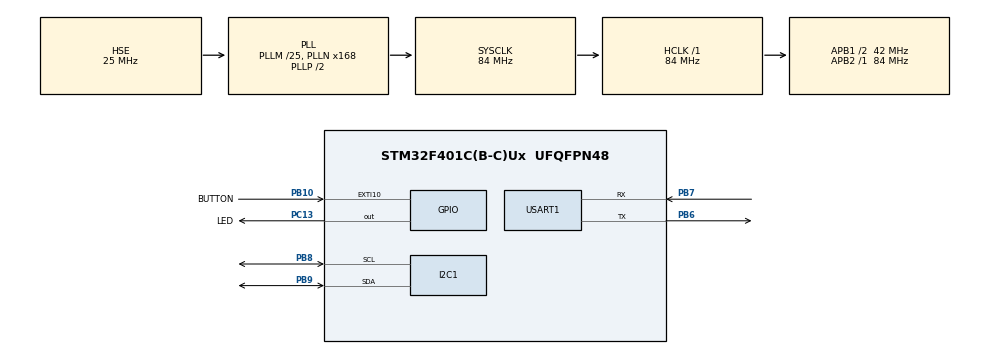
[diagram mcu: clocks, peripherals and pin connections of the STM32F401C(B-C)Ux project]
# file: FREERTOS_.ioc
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FREERTOS.BinarySemaphores01=semTrans,Dynamic,NULL
FREERTOS.Tasks01=TaskWrite,24,128,StartTaskWrite,Default,NULL,Dynamic,NULL,NULL;TaskRead,24,128,StartTaskRead,Default,NULL,Dynamic,NULL,NULL
FREERTOS.configTICK_RATE_HZ=500
FREERTOS.configUSE_NEWLIB_REENTRANT=1
Mcu.Family=STM32F4
Mcu.Name=STM32F401C(B-C)Ux
Mcu.Package=UFQFPN48
NVIC.EXTI15_10_IRQn=true\:5\:0\:false\:false\:true\:true\:true\:true\:true
NVIC.PriorityGroup=NVIC_PRIORITYGROUP_4
NVIC.RCC_IRQn=true\:5\:0\:false\:false\:true\:true\:true\:false\:true
PA13.Mode=Serial_Wire
PA13.Signal=SYS_JTMS-SWDIO
PA14.Mode=Serial_Wire
PA14.Signal=SYS_JTCK-SWCLK
PB10.GPIO_Label=BUTTON
PB10.GPIO_ModeDefaultEXTI=GPIO_MODE_IT_RISING_FALLING
PB10.Signal=GPXTI10
PB6.Mode=Asynchronous
PB6.Signal=USART1_TX
PB7.Mode=Asynchronous
PB7.Signal=USART1_RX
PB8.GPIO_Pu=GPIO_PULLUP
PB8.Mode=I2C
PB8.Signal=I2C1_SCL
PB9.GPIO_Pu=GPIO_PULLUP
PB9.Mode=I2C
PB9.Signal=I2C1_SDA
PC13-ANTI_TAMP.GPIO_Label=LED
PC13-ANTI_TAMP.Signal=GPIO_Output
PC14-OSC32_IN.Mode=LSE-External-Oscillator
PC14-OSC32_IN.Signal=RCC_OSC32_IN
PC15-OSC32_OUT.Mode=LSE-External-Oscillator
PC15-OSC32_OUT.Signal=RCC_OSC32_OUT
PH0\ -\ OSC_IN.Mode=HSE-External-Oscillator
PH0\ -\ OSC_IN.Signal=RCC_OSC_IN
PH1\ -\ OSC_OUT.Mode=HSE-External-Oscillator
PH1\ -\ OSC_OUT.Signal=RCC_OSC_OUT
ProjectManager.HeapSize=0x200
ProjectManager.StackSize=0x400
ProjectManager.TargetToolchain=STM32CubeIDE
RCC.48MHZClocksFreq_Value=42000000
RCC.AHBFreq_Value=84000000
RCC.APB1CLKDivider=RCC_HCLK_DIV2
RCC.APB1Freq_Value=42000000
RCC.APB1TimFreq_Value=84000000
RCC.APB2Freq_Value=84000000
RCC.APB2TimFreq_Value=84000000
RCC.CortexFreq_Value=84000000
RCC.HCLKFreq_Value=84000000
RCC.HSE_VALUE=25000000
RCC.HSI_VALUE=16000000
RCC.PLLM=25
RCC.PLLN=168
RCC.PLLSourceVirtual=RCC_PLLSOURCE_HSE
RCC.SYSCLKFreq_VALUE=84000000
RCC.SYSCLKSource=RCC_SYSCLKSOURCE_PLLCLK
RCC.VCOOutputFreq_Value=168000000
USART1.VirtualMode=VM_ASYNC
VP_FREERTOS_VS_CMSIS_V2.Mode=CMSIS_V2
VP_TIM4_VS_ClockSourceINT.Mode=Internal
board=custom

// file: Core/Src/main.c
/* USER CODE BEGIN Header */
/**
  ******************************************************************************
  * @file           : main.c
  * @brief          : Main program body
  ******************************************************************************
  * @attention
  *
  * Copyright (c) 2022 STMicroelectronics.
  * All rights reserved.
  *
  * This software is licensed under terms that can be found in the LICENSE file
  * in the root directory of this software component.
  * If no LICENSE file comes with this software, it is provided AS-IS.
  *
  ******************************************************************************
  */
/* USER CODE END Header */
#include "main.h"
#include <stdio.h>
#include <stdlib.h>
#include <string.h>
#include <math.h>
#include "baro.h"
#include "cmsis_os.h"

/* USER CODE BEGIN PD */
#define countof(_a)  (sizeof(_a) / sizeof(_a[0]))
/* USER CODE END PD */

I2C_HandleTypeDef hi2c1;

TIM_HandleTypeDef htim4;

UART_HandleTypeDef huart1;

/* Definitions for TaskWrite */
osThreadId_t TaskWriteHandle;
const osThreadAttr_t TaskWrite_attributes = {
  .name = "TaskWrite",
  .stack_size = 128 * 4,
  .priority = (osPriority_t) osPriorityNormal,
};
/* Definitions for TaskRead */
osThreadId_t TaskReadHandle;
const osThreadAttr_t TaskRead_attributes = {
  .name = "TaskRead",
  .stack_size = 128 * 4,
  .priority = (osPriority_t) osPriorityNormal,
};
/* Definitions for semTrans */
osSemaphoreId_t semTransHandle;
const osSemaphoreAttr_t semTrans_attributes = {
  .name = "semTrans"
};
/* USER CODE BEGIN PV */
char text[100];

/* USER CODE END PV */

void SystemClock_Config(void);
static void MX_GPIO_Init(void);
static void MX_USART1_UART_Init(void);
static void MX_I2C1_Init(void);
static void MX_TIM4_Init(void);
void StartTaskWrite(void *argument);
void StartTaskRead(void *argument);

int main(void)
{

  /* MCU Configuration--------------------------------------------------------*/

  /* Reset of all peripherals, Initializes the Flash interface and the Systick. */
  HAL_Init();

  /* Configure the system clock */
  SystemClock_Config();

  /* Initialize all configured peripherals */
  MX_GPIO_Init();
  MX_USART1_UART_Init();
  MX_I2C1_Init();
  MX_TIM4_Init();

  /* Init scheduler */
  osKernelInitialize();

  /* Create the semaphores(s) */
  /* creation of semTrans */
  semTransHandle = osSemaphoreNew(1, 1, &semTrans_attributes);

  /* Create the thread(s) */
  /* creation of TaskWrite */
  TaskWriteHandle = osThreadNew(StartTaskWrite, NULL, &TaskWrite_attributes);

  /* creation of TaskRead */
  TaskReadHandle = osThreadNew(StartTaskRead, NULL, &TaskRead_attributes);

  /* Start scheduler */
  osKernelStart();

  /* We should never get here as control is now taken by the scheduler */
  /* Infinite loop */
  while (1)
  {

  }
}

void SystemClock_Config(void)
{
  RCC_OscInitTypeDef RCC_OscInitStruct = {0};
  RCC_ClkInitTypeDef RCC_ClkInitStruct = {0};

  /** Configure the main internal regulator output voltage
  */
  __HAL_RCC_PWR_CLK_ENABLE();
  __HAL_PWR_VOLTAGESCALING_CONFIG(PWR_REGULATOR_VOLTAGE_SCALE2);

  /** Initializes the RCC Oscillators according to the specified parameters
  * in the RCC_OscInitTypeDef structure.
  */
  RCC_OscInitStruct.OscillatorType = RCC_OSCILLATORTYPE_HSE;
  RCC_OscInitStruct.HSEState = RCC_HSE_ON;
  RCC_OscInitStruct.PLL.PLLState = RCC_PLL_ON;
  RCC_OscInitStruct.PLL.PLLSource = RCC_PLLSOURCE_HSE;
  RCC_OscInitStruct.PLL.PLLM = 25;
  RCC_OscInitStruct.PLL.PLLN = 168;
  RCC_OscInitStruct.PLL.PLLP = RCC_PLLP_DIV2;
  RCC_OscInitStruct.PLL.PLLQ = 4;
  if (HAL_RCC_OscConfig(&RCC_OscInitStruct) != HAL_OK)
  {
    Error_Handler();
  }

  /** Initializes the CPU, AHB and APB buses clocks
  */
  RCC_ClkInitStruct.ClockType = RCC_CLOCKTYPE_HCLK|RCC_CLOCKTYPE_SYSCLK
                              |RCC_CLOCKTYPE_PCLK1|RCC_CLOCKTYPE_PCLK2;
  RCC_ClkInitStruct.SYSCLKSource = RCC_SYSCLKSOURCE_PLLCLK;
  RCC_ClkInitStruct.AHBCLKDivider = RCC_SYSCLK_DIV1;
  RCC_ClkInitStruct.APB1CLKDivider = RCC_HCLK_DIV2;
  RCC_ClkInitStruct.APB2CLKDivider = RCC_HCLK_DIV1;

  if (HAL_RCC_ClockConfig(&RCC_ClkInitStruct, FLASH_LATENCY_2) != HAL_OK)
  {
    Error_Handler();
  }
}

static void MX_I2C1_Init(void)
{

  hi2c1.Instance = I2C1;
  hi2c1.Init.ClockSpeed = 100000;
  hi2c1.Init.DutyCycle = I2C_DUTYCYCLE_2;
  hi2c1.Init.OwnAddress1 = 0;
  hi2c1.Init.AddressingMode = I2C_ADDRESSINGMODE_7BIT;
  hi2c1.Init.DualAddressMode = I2C_DUALADDRESS_DISABLE;
  hi2c1.Init.OwnAddress2 = 0;
  hi2c1.Init.GeneralCallMode = I2C_GENERALCALL_DISABLE;
  hi2c1.Init.NoStretchMode = I2C_NOSTRETCH_DISABLE;
  if (HAL_I2C_Init(&hi2c1) != HAL_OK)
  {
    Error_Handler();
  }

}

static void MX_TIM4_Init(void)
{

  TIM_ClockConfigTypeDef sClockSourceConfig = {0};
  TIM_MasterConfigTypeDef sMasterConfig = {0};

  htim4.Instance = TIM4;
  htim4.Init.Prescaler = 0;
  htim4.Init.CounterMode = TIM_COUNTERMODE_UP;
  htim4.Init.Period = 65535;
  htim4.Init.ClockDivision = TIM_CLOCKDIVISION_DIV1;
  htim4.Init.AutoReloadPreload = TIM_AUTORELOAD_PRELOAD_DISABLE;
  if (HAL_TIM_Base_Init(&htim4) != HAL_OK)
  {
    Error_Handler();
  }
  sClockSourceConfig.ClockSource = TIM_CLOCKSOURCE_INTERNAL;
  if (HAL_TIM_ConfigClockSource(&htim4, &sClockSourceConfig) != HAL_OK)
  {
    Error_Handler();
  }
  sMasterConfig.MasterOutputTrigger = TIM_TRGO_RESET;
  sMasterConfig.MasterSlaveMode = TIM_MASTERSLAVEMODE_DISABLE;
  if (HAL_TIMEx_MasterConfigSynchronization(&htim4, &sMasterConfig) != HAL_OK)
  {
    Error_Handler();
  }

}

static void MX_USART1_UART_Init(void)
{

  huart1.Instance = USART1;
  huart1.Init.BaudRate = 115200;
  huart1.Init.WordLength = UART_WORDLENGTH_8B;
  huart1.Init.StopBits = UART_STOPBITS_1;
  huart1.Init.Parity = UART_PARITY_NONE;
  huart1.Init.Mode = UART_MODE_TX_RX;
  huart1.Init.HwFlowCtl = UART_HWCONTROL_NONE;
  huart1.Init.OverSampling = UART_OVERSAMPLING_16;
  if (HAL_UART_Init(&huart1) != HAL_OK)
  {
    Error_Handler();
  }

}

static void MX_GPIO_Init(void)
{
  GPIO_InitTypeDef GPIO_InitStruct = {0};

  /* GPIO Ports Clock Enable */
  __HAL_RCC_GPIOC_CLK_ENABLE();
  __HAL_RCC_GPIOH_CLK_ENABLE();
  __HAL_RCC_GPIOB_CLK_ENABLE();
  __HAL_RCC_GPIOA_CLK_ENABLE();

  /*Configure GPIO pin Output Level */
  HAL_GPIO_WritePin(LED_GPIO_Port, LED_Pin, GPIO_PIN_RESET);

  /*Configure GPIO pin : LED_Pin */
  GPIO_InitStruct.Pin = LED_Pin;
  GPIO_InitStruct.Mode = GPIO_MODE_OUTPUT_PP;
  GPIO_InitStruct.Pull = GPIO_NOPULL;
  GPIO_InitStruct.Speed = GPIO_SPEED_FREQ_LOW;
  HAL_GPIO_Init(LED_GPIO_Port, &GPIO_InitStruct);

  /*Configure GPIO pin : BUTTON_Pin */
  GPIO_InitStruct.Pin = BUTTON_Pin;
  GPIO_InitStruct.Mode = GPIO_MODE_IT_RISING_FALLING;
  GPIO_InitStruct.Pull = GPIO_NOPULL;
  HAL_GPIO_Init(BUTTON_GPIO_Port, &GPIO_InitStruct);

  /* EXTI interrupt init*/
  HAL_NVIC_SetPriority(EXTI15_10_IRQn, 5, 0);
  HAL_NVIC_EnableIRQ(EXTI15_10_IRQn);

}

/* USER CODE BEGIN 4 */
void HAL_GPIO_EXTI_Callback(uint16_t GPIO_Pin)
{
  osSemaphoreRelease(semTransHandle);
}
/* USER CODE END 4 */

int32_t temp;
int32_t pres;
void StartTaskWrite(void *argument)
{
  /* USER CODE BEGIN 5 */
  /* Infinite loop */
  for(;;)
  {
	if (baro_init() != BARO_OK)
	{
		snprintf(text, countof(text), "Error init baro\n");
		HAL_UART_Transmit(&huart1, (uint8_t*)text, strnlen(text, countof(text)), 1000);
		while (1) {}
	}
    temp = baro_read_temp();
    pres = baro_read_press();
    //snprintf(text, countof(text), "/*%ld.%02ld,%ld.%02ld*/\n", temp/100, temp%100, pres/100, pres%100);

	//HAL_GPIO_TogglePin(LED_GPIO_Port, LED_Pin);
	//osDelay(pdMS_TO_TICKS(1000));
  }
  /* USER CODE END 5 */
}

void StartTaskRead(void *argument)
{
  /* USER CODE BEGIN StartTaskRead */
  /* Infinite loop */
  for(;;)
  {
	//osSemaphoreAcquire(semTransHandle, osWaitForever);
	snprintf(text, countof(text), "/*%ld.%02ld,%ld.%02ld*/\n", temp/100, temp%100, pres/100, pres%100);
	HAL_UART_Transmit(&huart1, (uint8_t*)text, strlen(text), 1000);
  /* USER CODE END StartTaskRead */
}
}

void Error_Handler(void)
{
  __disable_irq();
  while (1)
  {
  }
}
